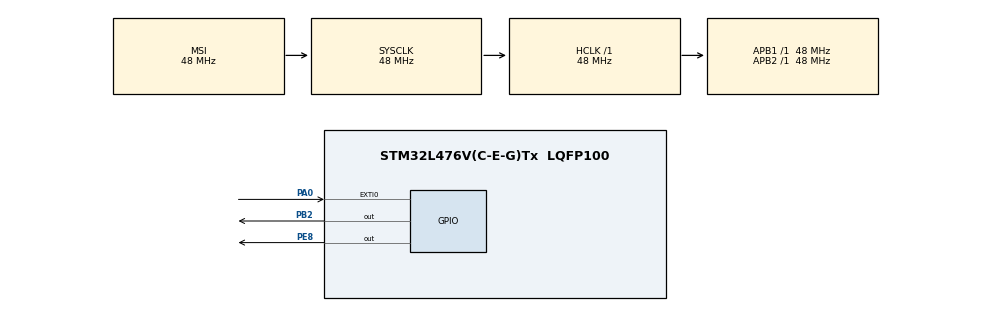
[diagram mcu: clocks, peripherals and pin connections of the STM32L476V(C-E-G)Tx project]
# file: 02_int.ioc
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Mcu.Family=STM32L4
Mcu.Name=STM32L476V(C-E-G)Tx
Mcu.Package=LQFP100
NVIC.EXTI0_IRQn=true\:0\:0\:false\:false\:true
NVIC.PriorityGroup=NVIC_PRIORITYGROUP_4
NVIC.RCC_IRQn=true\:0\:0\:false\:false\:true
PA0.Signal=GPXTI0
PB2.Signal=GPIO_Output
PE8.Signal=GPIO_Output
ProjectManager.HeapSize=0x200
ProjectManager.StackSize=0x400
ProjectManager.TargetToolchain=EWARM
RCC.ADCFreq_Value=192000000
RCC.AHBFreq_Value=48000000
RCC.APB1Freq_Value=48000000
RCC.APB1TimFreq_Value=48000000
RCC.APB2Freq_Value=48000000
RCC.APB2TimFreq_Value=48000000
RCC.CortexFreq_Value=48000000
RCC.HCLKFreq_Value=48000000
RCC.HSE_VALUE=8000000
RCC.HSI_VALUE=16000000
RCC.LSE_VALUE=32768
RCC.MSIClockRange=RCC_MSIRANGE_11
RCC.MSI_VALUE=48000000
RCC.PREFETCH_ENABLE=1
RCC.SYSCLKFreq_VALUE=48000000
RCC.USBFreq_Value=192000000
RCC.VCOOutputFreq_Value=384000000
board=STM32L476G-DISCO

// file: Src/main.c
/**
  ******************************************************************************
  * File Name          : main.c
  * Description        : Main program body
  ******************************************************************************
  *
  * COPYRIGHT(c) 2018 STMicroelectronics
  *
  * Redistribution and use in source and binary forms, with or without modification,
  * are permitted provided that the following conditions are met:
  *   1. Redistributions of source code must retain the above copyright notice,
  *      this list of conditions and the following disclaimer.
  *   2. Redistributions in binary form must reproduce the above copyright notice,
  *      this list of conditions and the following disclaimer in the documentation
  *      and/or other materials provided with the distribution.
  *   3. Neither the name of STMicroelectronics nor the names of its contributors
  *      may be used to endorse or promote products derived from this software
  *      without specific prior written permission.
  *
  * THIS SOFTWARE IS PROVIDED BY THE COPYRIGHT HOLDERS AND CONTRIBUTORS "AS IS"
  * AND ANY EXPRESS OR IMPLIED WARRANTIES, INCLUDING, BUT NOT LIMITED TO, THE
  * IMPLIED WARRANTIES OF MERCHANTABILITY AND FITNESS FOR A PARTICULAR PURPOSE ARE
  * DISCLAIMED. IN NO EVENT SHALL THE COPYRIGHT HOLDER OR CONTRIBUTORS BE LIABLE
  * FOR ANY DIRECT, INDIRECT, INCIDENTAL, SPECIAL, EXEMPLARY, OR CONSEQUENTIAL
  * DAMAGES (INCLUDING, BUT NOT LIMITED TO, PROCUREMENT OF SUBSTITUTE GOODS OR
  * SERVICES; LOSS OF USE, DATA, OR PROFITS; OR BUSINESS INTERRUPTION) HOWEVER
  * CAUSED AND ON ANY THEORY OF LIABILITY, WHETHER IN CONTRACT, STRICT LIABILITY,
  * OR TORT (INCLUDING NEGLIGENCE OR OTHERWISE) ARISING IN ANY WAY OUT OF THE USE
  * OF THIS SOFTWARE, EVEN IF ADVISED OF THE POSSIBILITY OF SUCH DAMAGE.
  *
  ******************************************************************************
  */
#include "stm32l4xx_hal.h"

void SystemClock_Config(void);
void Error_Handler(void);
static void MX_GPIO_Init(void);

int main(void)
{
  /* MCU Configuration----------------------------------------------------------*/

  /* Reset of all peripherals, Initializes the Flash interface and the Systick. */
  HAL_Init();

  /* Configure the system clock */
  SystemClock_Config();

  /* Initialize all configured peripherals */
  MX_GPIO_Init();

  /* Infinite loop */
  while (1)
  {

  /* USER CODE BEGIN 3 */
  HAL_GPIO_TogglePin(GPIOE,GPIO_PIN_8);
  HAL_Delay(500);
  }
  /* USER CODE END 3 */

}

/** System Clock Configuration
*/
void SystemClock_Config(void)
{

  RCC_OscInitTypeDef RCC_OscInitStruct;
  RCC_ClkInitTypeDef RCC_ClkInitStruct;

  RCC_OscInitStruct.OscillatorType = RCC_OSCILLATORTYPE_MSI;
  RCC_OscInitStruct.MSIState = RCC_MSI_ON;
  RCC_OscInitStruct.MSICalibrationValue = 0;
  RCC_OscInitStruct.MSIClockRange = RCC_MSIRANGE_11;
  RCC_OscInitStruct.PLL.PLLState = RCC_PLL_NONE;
  if (HAL_RCC_OscConfig(&RCC_OscInitStruct) != HAL_OK)
  {
    Error_Handler();
  }

  RCC_ClkInitStruct.ClockType = RCC_CLOCKTYPE_HCLK|RCC_CLOCKTYPE_SYSCLK
                              |RCC_CLOCKTYPE_PCLK1|RCC_CLOCKTYPE_PCLK2;
  RCC_ClkInitStruct.SYSCLKSource = RCC_SYSCLKSOURCE_MSI;
  RCC_ClkInitStruct.AHBCLKDivider = RCC_SYSCLK_DIV1;
  RCC_ClkInitStruct.APB1CLKDivider = RCC_HCLK_DIV1;
  RCC_ClkInitStruct.APB2CLKDivider = RCC_HCLK_DIV1;
  if (HAL_RCC_ClockConfig(&RCC_ClkInitStruct, FLASH_LATENCY_2) != HAL_OK)
  {
    Error_Handler();
  }

  __HAL_RCC_PWR_CLK_ENABLE();

  if (HAL_PWREx_ControlVoltageScaling(PWR_REGULATOR_VOLTAGE_SCALE1) != HAL_OK)
  {
    Error_Handler();
  }

  HAL_SYSTICK_Config(HAL_RCC_GetHCLKFreq()/1000);

  HAL_SYSTICK_CLKSourceConfig(SYSTICK_CLKSOURCE_HCLK);

  /* SysTick_IRQn interrupt configuration */
  HAL_NVIC_SetPriority(SysTick_IRQn, 0, 0);
}

/** Configure pins as
        * Analog
        * Input
        * Output
        * EVENT_OUT
        * EXTI
*/
static void MX_GPIO_Init(void)
{

  GPIO_InitTypeDef GPIO_InitStruct;

  /* GPIO Ports Clock Enable */
  __HAL_RCC_GPIOA_CLK_ENABLE();
  __HAL_RCC_GPIOB_CLK_ENABLE();
  __HAL_RCC_GPIOE_CLK_ENABLE();

  /*Configure GPIO pin : PA0 */
  GPIO_InitStruct.Pin = GPIO_PIN_0;
  GPIO_InitStruct.Mode = GPIO_MODE_IT_RISING;
  GPIO_InitStruct.Pull = GPIO_NOPULL;
  HAL_GPIO_Init(GPIOA, &GPIO_InitStruct);

  /*Configure GPIO pin : PB2 */
  GPIO_InitStruct.Pin = GPIO_PIN_2;
  GPIO_InitStruct.Mode = GPIO_MODE_OUTPUT_PP;
  GPIO_InitStruct.Pull = GPIO_NOPULL;
  GPIO_InitStruct.Speed = GPIO_SPEED_FREQ_LOW;
  HAL_GPIO_Init(GPIOB, &GPIO_InitStruct);

  /*Configure GPIO pin : PE8 */
  GPIO_InitStruct.Pin = GPIO_PIN_8;
  GPIO_InitStruct.Mode = GPIO_MODE_OUTPUT_PP;
  GPIO_InitStruct.Pull = GPIO_NOPULL;
  GPIO_InitStruct.Speed = GPIO_SPEED_FREQ_LOW;
  HAL_GPIO_Init(GPIOE, &GPIO_InitStruct);

  /*Configure GPIO pin Output Level */
  HAL_GPIO_WritePin(GPIOB, GPIO_PIN_2, GPIO_PIN_RESET);

  /*Configure GPIO pin Output Level */
  HAL_GPIO_WritePin(GPIOE, GPIO_PIN_8, GPIO_PIN_RESET);

  /* EXTI interrupt init*/
  HAL_NVIC_SetPriority(EXTI0_IRQn, 0, 0);
  HAL_NVIC_EnableIRQ(EXTI0_IRQn);

}

/* USER CODE BEGIN 4 */
void HAL_GPIO_EXTI_Callback(uint16_t GPIO_Pin)
{
  /* Prevent unused argument(s) compilation warning */
  HAL_GPIO_TogglePin(GPIOB,GPIO_PIN_2);
  UNUSED(GPIO_Pin);

  /* NOTE: This function should not be modified, when the callback is needed,
           the HAL_GPIO_EXTI_Callback could be implemented in the user file
   */
}
/* USER CODE END 4 */

void Error_Handler(void)
{
  while(1)
  {
  }
}

/************************ (C) COPYRIGHT STMicroelectronics *****END OF FILE****/
